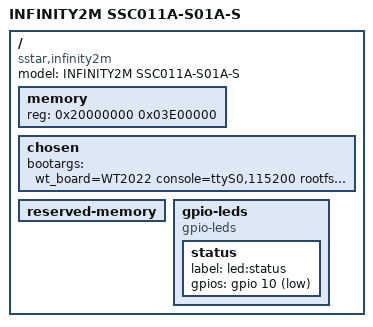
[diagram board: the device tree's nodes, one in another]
/*
* infinity2m-spinand-ssc011a-s01a-display.dts- Sigmastar
*
* Copyright (c) [2019~2020] SigmaStar Technology.
*
*
* This software is licensed under the terms of the GNU General Public
* License version 2, as published by the Free Software Foundation, and
* may be copied, distributed, and modified under those terms.
*
* This program is distributed in the hope that it will be useful,
* but WITHOUT ANY WARRANTY; without even the implied warranty of
* MERCHANTABILITY or FITNESS FOR A PARTICULAR PURPOSE.  See the
* GNU General Public License version 2 for more details.
*
*/

/dts-v1/;
#include "WT2022.dtsi"
#include "WT2022-display.dtsi"
#include "WT2022-padmux-display.dtsi"

/ {
    model = "INFINITY2M SSC011A-S01A-S";
    compatible = "sstar,infinity2m";

    /* memory setting will be replaced with LX_MEM*/
    memory {
        reg = <0x20000000 0x03E00000>;
    };
	/* this cmdline will be replaced with uboot bootargs*/
    chosen {
        bootargs = "wt_board=WT2022 console=ttyS0,115200 rootfstype=squashfs,ubifs rootwait=1 LX_MEM=0x7f00000 mma_heap=mma_heap_name0,miu=0,sz=0x1500000 mma_memblock_remove=1 highres=off mmap_reserved=fb,miu=0,sz=0x300000,max_start_off=0x7C00000,max_end_off=0x7F00000";
    };

    /*!!IMPORTANT!! The reserved memory must be 1MB aligned*/
    reserved-memory {
        #address-cells = <1>;
        #size-cells = <1>;
        ranges;

        /*cma0 {
            compatible = "shared-dma-pool";
            size = <0x400000>;
            reusable;
            alignment = <0x1000>;
            linux,cma-default;
        };*/
    };


    gpio-leds {
        compatible = "gpio-leds";

        status {
            label = "led:status";
            gpios = <&gpio 10 1>;
        };
    };

};
